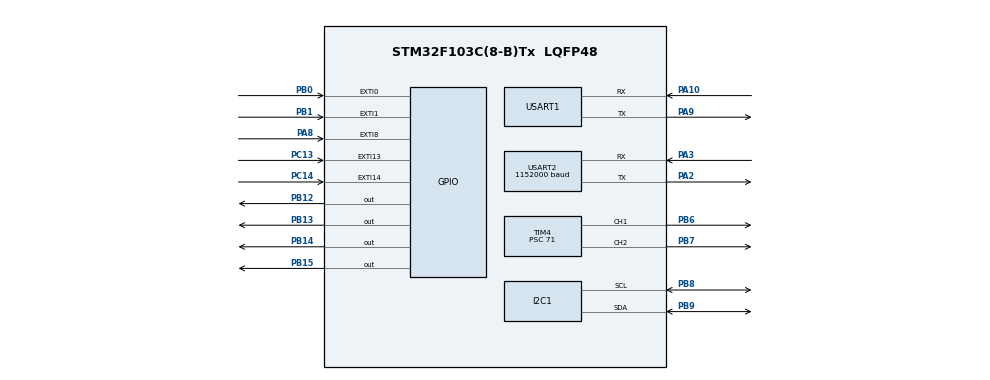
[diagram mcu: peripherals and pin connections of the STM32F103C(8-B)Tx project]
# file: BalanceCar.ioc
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Mcu.Family=STM32F1
Mcu.Name=STM32F103C(8-B)Tx
Mcu.Package=LQFP48
NVIC.EXTI0_IRQn=true\:0\:0\:true\:false\:true\:true\:true
NVIC.EXTI15_10_IRQn=true\:0\:0\:true\:false\:true\:true\:true
NVIC.EXTI1_IRQn=true\:0\:0\:true\:false\:true\:true\:true
NVIC.EXTI9_5_IRQn=true\:1\:0\:true\:false\:true\:true\:true
NVIC.PriorityGroup=NVIC_PRIORITYGROUP_4
NVIC.TIM2_IRQn=true\:2\:0\:true\:false\:true\:true\:true
NVIC.USART1_IRQn=true\:1\:0\:true\:false\:true\:true\:true
NVIC.USART2_IRQn=true\:0\:0\:true\:false\:true\:true\:true
PA10.Mode=Asynchronous
PA10.Signal=USART1_RX
PA13.Mode=Serial_Wire
PA13.Signal=SYS_JTMS-SWDIO
PA14.Mode=Serial_Wire
PA14.Signal=SYS_JTCK-SWCLK
PA2.Mode=Asynchronous
PA2.Signal=USART2_TX
PA3.Mode=Asynchronous
PA3.Signal=USART2_RX
PA8.GPIO_ModeDefaultEXTI=GPIO_MODE_IT_FALLING
PA8.GPIO_PuPd=GPIO_NOPULL
PA8.Signal=GPXTI8
PA9.Mode=Asynchronous
PA9.Signal=USART1_TX
PB0.GPIO_PuPd=GPIO_PULLDOWN
PB0.Signal=GPXTI0
PB1.GPIO_PuPd=GPIO_PULLDOWN
PB1.Signal=GPXTI1
PB12.Signal=GPIO_Output
PB13.Signal=GPIO_Output
PB14.Signal=GPIO_Output
PB15.Signal=GPIO_Output
PB6.Signal=S_TIM4_CH1
PB7.Signal=S_TIM4_CH2
PB8.Mode=I2C
PB8.Signal=I2C1_SCL
PB9.Mode=I2C
PB9.Signal=I2C1_SDA
PC13-TAMPER-RTC.Signal=GPXTI13
PC14-OSC32_IN.Signal=GPXTI14
PD0-OSC_IN.Mode=HSE-External-Oscillator
PD0-OSC_IN.Signal=RCC_OSC_IN
PD1-OSC_OUT.Mode=HSE-External-Oscillator
PD1-OSC_OUT.Signal=RCC_OSC_OUT
ProjectManager.HeapSize=0x200
ProjectManager.StackSize=0x400
ProjectManager.TargetToolchain=STM32CubeIDE
RCC.AHBFreq_Value=72000000
RCC.APB1CLKDivider=RCC_HCLK_DIV2
RCC.APB1Freq_Value=36000000
RCC.APB1TimFreq_Value=72000000
RCC.APB2Freq_Value=72000000
RCC.APB2TimFreq_Value=72000000
RCC.HCLKFreq_Value=72000000
RCC.PLLMUL=RCC_PLL_MUL9
RCC.PLLSourceVirtual=RCC_PLLSOURCE_HSE
RCC.SYSCLKFreq_VALUE=72000000
RCC.SYSCLKSource=RCC_SYSCLKSOURCE_PLLCLK
RCC.USBFreq_Value=72000000
SH.S_TIM4_CH1.0=TIM4_CH1,PWM Generation1 CH1
SH.S_TIM4_CH2.0=TIM4_CH2,PWM Generation2 CH2
TIM4.Channel-PWM\ Generation1\ CH1=TIM_CHANNEL_1
TIM4.Channel-PWM\ Generation2\ CH2=TIM_CHANNEL_2
TIM4.Period=999
TIM4.Prescaler=71
USART1.VirtualMode=VM_ASYNC
USART2.BaudRate=1152000
USART2.VirtualMode=VM_ASYNC
VP_TIM2_VS_ClockSourceINT.Mode=Internal
board=custom

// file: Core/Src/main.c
/* USER CODE BEGIN Header */
/**
  ******************************************************************************
  * @file           : main.c
  * @brief          : Main program body
  ******************************************************************************
  * @attention
  *
  * <h2><center>&copy; Copyright (c) 2021 STMicroelectronics.
  * All rights reserved.</center></h2>
  *
  * This software component is licensed by ST under BSD 3-Clause license,
  * the "License"; You may not use this file except in compliance with the
  * License. You may obtain a copy of the License at:
  *                        opensource.org/licenses/BSD-3-Clause
  *
  ******************************************************************************
  */
/* USER CODE END Header */
#include "main.h"

/* USER CODE BEGIN Includes */
#include "App.h"
/* USER CODE END Includes */

I2C_HandleTypeDef hi2c1;

void SystemClock_Config(void);
static void MX_GPIO_Init(void);
static void MX_TIM2_Init(void);
static void MX_TIM4_Init(void);
static void MX_USART1_UART_Init(void);
static void MX_USART2_UART_Init(void);
static void MX_I2C1_Init(void);

int main(void)
{

  /* MCU Configuration--------------------------------------------------------*/

  /* Reset of all peripherals, Initializes the Flash interface and the Systick. */
  HAL_Init();

  /* Configure the system clock */
  SystemClock_Config();

  /* Initialize all configured peripherals */
  MX_GPIO_Init();
  MX_TIM2_Init();
  MX_TIM4_Init();
  MX_USART1_UART_Init();
  MX_USART2_UART_Init();
  MX_I2C1_Init();
  /* USER CODE BEGIN 2 */

  App();
  /* USER CODE END 2 */

  /* Infinite loop */
  while (1)
  {

  }
}

void SystemClock_Config(void)
{
  LL_FLASH_SetLatency(LL_FLASH_LATENCY_2);
  while(LL_FLASH_GetLatency()!= LL_FLASH_LATENCY_2)
  {
  }
  LL_RCC_HSE_Enable();

   /* Wait till HSE is ready */
  while(LL_RCC_HSE_IsReady() != 1)
  {

  }
  LL_RCC_PLL_ConfigDomain_SYS(LL_RCC_PLLSOURCE_HSE_DIV_1, LL_RCC_PLL_MUL_9);
  LL_RCC_PLL_Enable();

   /* Wait till PLL is ready */
  while(LL_RCC_PLL_IsReady() != 1)
  {

  }
  LL_RCC_SetAHBPrescaler(LL_RCC_SYSCLK_DIV_1);
  LL_RCC_SetAPB1Prescaler(LL_RCC_APB1_DIV_2);
  LL_RCC_SetAPB2Prescaler(LL_RCC_APB2_DIV_1);
  LL_RCC_SetSysClkSource(LL_RCC_SYS_CLKSOURCE_PLL);

   /* Wait till System clock is ready */
  while(LL_RCC_GetSysClkSource() != LL_RCC_SYS_CLKSOURCE_STATUS_PLL)
  {

  }
  LL_SetSystemCoreClock(72000000);

   /* Update the time base */
  if (HAL_InitTick (TICK_INT_PRIORITY) != HAL_OK)
  {
    Error_Handler();
  }
}

static void MX_I2C1_Init(void)
{

  hi2c1.Instance = I2C1;
  hi2c1.Init.ClockSpeed = 100000;
  hi2c1.Init.DutyCycle = I2C_DUTYCYCLE_2;
  hi2c1.Init.OwnAddress1 = 0;
  hi2c1.Init.AddressingMode = I2C_ADDRESSINGMODE_7BIT;
  hi2c1.Init.DualAddressMode = I2C_DUALADDRESS_DISABLE;
  hi2c1.Init.OwnAddress2 = 0;
  hi2c1.Init.GeneralCallMode = I2C_GENERALCALL_DISABLE;
  hi2c1.Init.NoStretchMode = I2C_NOSTRETCH_DISABLE;
  if (HAL_I2C_Init(&hi2c1) != HAL_OK)
  {
    Error_Handler();
  }

}

static void MX_TIM2_Init(void)
{

  LL_TIM_InitTypeDef TIM_InitStruct = {0};

  /* Peripheral clock enable */
  LL_APB1_GRP1_EnableClock(LL_APB1_GRP1_PERIPH_TIM2);

  /* TIM2 interrupt Init */
  NVIC_SetPriority(TIM2_IRQn, NVIC_EncodePriority(NVIC_GetPriorityGrouping(),2, 0));
  NVIC_EnableIRQ(TIM2_IRQn);

  TIM_InitStruct.Prescaler = 0;
  TIM_InitStruct.CounterMode = LL_TIM_COUNTERMODE_UP;
  TIM_InitStruct.Autoreload = 65535;
  TIM_InitStruct.ClockDivision = LL_TIM_CLOCKDIVISION_DIV1;
  LL_TIM_Init(TIM2, &TIM_InitStruct);
  LL_TIM_DisableARRPreload(TIM2);
  LL_TIM_SetClockSource(TIM2, LL_TIM_CLOCKSOURCE_INTERNAL);
  LL_TIM_SetTriggerOutput(TIM2, LL_TIM_TRGO_RESET);
  LL_TIM_DisableMasterSlaveMode(TIM2);

}

static void MX_TIM4_Init(void)
{

  LL_TIM_InitTypeDef TIM_InitStruct = {0};
  LL_TIM_OC_InitTypeDef TIM_OC_InitStruct = {0};

  LL_GPIO_InitTypeDef GPIO_InitStruct = {0};

  /* Peripheral clock enable */
  LL_APB1_GRP1_EnableClock(LL_APB1_GRP1_PERIPH_TIM4);

  TIM_InitStruct.Prescaler = 71;
  TIM_InitStruct.CounterMode = LL_TIM_COUNTERMODE_UP;
  TIM_InitStruct.Autoreload = 999;
  TIM_InitStruct.ClockDivision = LL_TIM_CLOCKDIVISION_DIV1;
  LL_TIM_Init(TIM4, &TIM_InitStruct);
  LL_TIM_DisableARRPreload(TIM4);
  LL_TIM_OC_EnablePreload(TIM4, LL_TIM_CHANNEL_CH1);
  TIM_OC_InitStruct.OCMode = LL_TIM_OCMODE_PWM1;
  TIM_OC_InitStruct.OCState = LL_TIM_OCSTATE_DISABLE;
  TIM_OC_InitStruct.OCNState = LL_TIM_OCSTATE_DISABLE;
  TIM_OC_InitStruct.CompareValue = 0;
  TIM_OC_InitStruct.OCPolarity = LL_TIM_OCPOLARITY_HIGH;
  LL_TIM_OC_Init(TIM4, LL_TIM_CHANNEL_CH1, &TIM_OC_InitStruct);
  LL_TIM_OC_DisableFast(TIM4, LL_TIM_CHANNEL_CH1);
  LL_TIM_OC_EnablePreload(TIM4, LL_TIM_CHANNEL_CH2);
  LL_TIM_OC_Init(TIM4, LL_TIM_CHANNEL_CH2, &TIM_OC_InitStruct);
  LL_TIM_OC_DisableFast(TIM4, LL_TIM_CHANNEL_CH2);
  LL_TIM_SetTriggerOutput(TIM4, LL_TIM_TRGO_RESET);
  LL_TIM_DisableMasterSlaveMode(TIM4);
  LL_APB2_GRP1_EnableClock(LL_APB2_GRP1_PERIPH_GPIOB);
  /**TIM4 GPIO Configuration
  PB6   ------> TIM4_CH1
  PB7   ------> TIM4_CH2
  */
  GPIO_InitStruct.Pin = LL_GPIO_PIN_6|LL_GPIO_PIN_7;
  GPIO_InitStruct.Mode = LL_GPIO_MODE_ALTERNATE;
  GPIO_InitStruct.Speed = LL_GPIO_SPEED_FREQ_LOW;
  GPIO_InitStruct.OutputType = LL_GPIO_OUTPUT_PUSHPULL;
  LL_GPIO_Init(GPIOB, &GPIO_InitStruct);

}

static void MX_USART1_UART_Init(void)
{

  LL_USART_InitTypeDef USART_InitStruct = {0};

  LL_GPIO_InitTypeDef GPIO_InitStruct = {0};

  /* Peripheral clock enable */
  LL_APB2_GRP1_EnableClock(LL_APB2_GRP1_PERIPH_USART1);

  LL_APB2_GRP1_EnableClock(LL_APB2_GRP1_PERIPH_GPIOA);
  /**USART1 GPIO Configuration
  PA9   ------> USART1_TX
  PA10   ------> USART1_RX
  */
  GPIO_InitStruct.Pin = LL_GPIO_PIN_9;
  GPIO_InitStruct.Mode = LL_GPIO_MODE_ALTERNATE;
  GPIO_InitStruct.Speed = LL_GPIO_SPEED_FREQ_HIGH;
  GPIO_InitStruct.OutputType = LL_GPIO_OUTPUT_PUSHPULL;
  LL_GPIO_Init(GPIOA, &GPIO_InitStruct);

  GPIO_InitStruct.Pin = LL_GPIO_PIN_10;
  GPIO_InitStruct.Mode = LL_GPIO_MODE_FLOATING;
  LL_GPIO_Init(GPIOA, &GPIO_InitStruct);

  /* USART1 interrupt Init */
  NVIC_SetPriority(USART1_IRQn, NVIC_EncodePriority(NVIC_GetPriorityGrouping(),1, 0));
  NVIC_EnableIRQ(USART1_IRQn);

  USART_InitStruct.BaudRate = 115200;
  USART_InitStruct.DataWidth = LL_USART_DATAWIDTH_8B;
  USART_InitStruct.StopBits = LL_USART_STOPBITS_1;
  USART_InitStruct.Parity = LL_USART_PARITY_NONE;
  USART_InitStruct.TransferDirection = LL_USART_DIRECTION_TX_RX;
  USART_InitStruct.HardwareFlowControl = LL_USART_HWCONTROL_NONE;
  USART_InitStruct.OverSampling = LL_USART_OVERSAMPLING_16;
  LL_USART_Init(USART1, &USART_InitStruct);
  LL_USART_ConfigAsyncMode(USART1);
  LL_USART_Enable(USART1);

}

static void MX_USART2_UART_Init(void)
{

  LL_USART_InitTypeDef USART_InitStruct = {0};

  LL_GPIO_InitTypeDef GPIO_InitStruct = {0};

  /* Peripheral clock enable */
  LL_APB1_GRP1_EnableClock(LL_APB1_GRP1_PERIPH_USART2);

  LL_APB2_GRP1_EnableClock(LL_APB2_GRP1_PERIPH_GPIOA);
  /**USART2 GPIO Configuration
  PA2   ------> USART2_TX
  PA3   ------> USART2_RX
  */
  GPIO_InitStruct.Pin = LL_GPIO_PIN_2;
  GPIO_InitStruct.Mode = LL_GPIO_MODE_ALTERNATE;
  GPIO_InitStruct.Speed = LL_GPIO_SPEED_FREQ_HIGH;
  GPIO_InitStruct.OutputType = LL_GPIO_OUTPUT_PUSHPULL;
  LL_GPIO_Init(GPIOA, &GPIO_InitStruct);

  GPIO_InitStruct.Pin = LL_GPIO_PIN_3;
  GPIO_InitStruct.Mode = LL_GPIO_MODE_FLOATING;
  LL_GPIO_Init(GPIOA, &GPIO_InitStruct);

  /* USART2 interrupt Init */
  NVIC_SetPriority(USART2_IRQn, NVIC_EncodePriority(NVIC_GetPriorityGrouping(),0, 0));
  NVIC_EnableIRQ(USART2_IRQn);

  USART_InitStruct.BaudRate = 1152000;
  USART_InitStruct.DataWidth = LL_USART_DATAWIDTH_8B;
  USART_InitStruct.StopBits = LL_USART_STOPBITS_1;
  USART_InitStruct.Parity = LL_USART_PARITY_NONE;
  USART_InitStruct.TransferDirection = LL_USART_DIRECTION_TX_RX;
  USART_InitStruct.HardwareFlowControl = LL_USART_HWCONTROL_NONE;
  USART_InitStruct.OverSampling = LL_USART_OVERSAMPLING_16;
  LL_USART_Init(USART2, &USART_InitStruct);
  LL_USART_ConfigAsyncMode(USART2);
  LL_USART_Enable(USART2);
  /* USER CODE BEGIN USART2_Init 2 */
  LL_USART_ClearFlag_RXNE(USART2);
  LL_USART_EnableIT_RXNE(USART2);
  /* USER CODE END USART2_Init 2 */

}

static void MX_GPIO_Init(void)
{
  LL_EXTI_InitTypeDef EXTI_InitStruct = {0};
  LL_GPIO_InitTypeDef GPIO_InitStruct = {0};

  /* GPIO Ports Clock Enable */
  LL_APB2_GRP1_EnableClock(LL_APB2_GRP1_PERIPH_GPIOC);
  LL_APB2_GRP1_EnableClock(LL_APB2_GRP1_PERIPH_GPIOD);
  LL_APB2_GRP1_EnableClock(LL_APB2_GRP1_PERIPH_GPIOA);
  LL_APB2_GRP1_EnableClock(LL_APB2_GRP1_PERIPH_GPIOB);

  /**/
  LL_GPIO_ResetOutputPin(GPIOB, LL_GPIO_PIN_12|LL_GPIO_PIN_13|LL_GPIO_PIN_14|LL_GPIO_PIN_15);

  /**/
  LL_GPIO_AF_SetEXTISource(LL_GPIO_AF_EXTI_PORTC, LL_GPIO_AF_EXTI_LINE13);

  /**/
  LL_GPIO_AF_SetEXTISource(LL_GPIO_AF_EXTI_PORTC, LL_GPIO_AF_EXTI_LINE14);

  /**/
  LL_GPIO_AF_SetEXTISource(LL_GPIO_AF_EXTI_PORTB, LL_GPIO_AF_EXTI_LINE0);

  /**/
  LL_GPIO_AF_SetEXTISource(LL_GPIO_AF_EXTI_PORTB, LL_GPIO_AF_EXTI_LINE1);

  /**/
  LL_GPIO_AF_SetEXTISource(LL_GPIO_AF_EXTI_PORTA, LL_GPIO_AF_EXTI_LINE8);

  /**/
  EXTI_InitStruct.Line_0_31 = LL_EXTI_LINE_13;
  EXTI_InitStruct.LineCommand = ENABLE;
  EXTI_InitStruct.Mode = LL_EXTI_MODE_IT;
  EXTI_InitStruct.Trigger = LL_EXTI_TRIGGER_RISING;
  LL_EXTI_Init(&EXTI_InitStruct);

  /**/
  EXTI_InitStruct.Line_0_31 = LL_EXTI_LINE_14;
  EXTI_InitStruct.LineCommand = ENABLE;
  EXTI_InitStruct.Mode = LL_EXTI_MODE_IT;
  EXTI_InitStruct.Trigger = LL_EXTI_TRIGGER_RISING;
  LL_EXTI_Init(&EXTI_InitStruct);

  /**/
  EXTI_InitStruct.Line_0_31 = LL_EXTI_LINE_0;
  EXTI_InitStruct.LineCommand = ENABLE;
  EXTI_InitStruct.Mode = LL_EXTI_MODE_IT;
  EXTI_InitStruct.Trigger = LL_EXTI_TRIGGER_RISING;
  LL_EXTI_Init(&EXTI_InitStruct);

  /**/
  EXTI_InitStruct.Line_0_31 = LL_EXTI_LINE_1;
  EXTI_InitStruct.LineCommand = ENABLE;
  EXTI_InitStruct.Mode = LL_EXTI_MODE_IT;
  EXTI_InitStruct.Trigger = LL_EXTI_TRIGGER_RISING;
  LL_EXTI_Init(&EXTI_InitStruct);

  /**/
  EXTI_InitStruct.Line_0_31 = LL_EXTI_LINE_8;
  EXTI_InitStruct.LineCommand = ENABLE;
  EXTI_InitStruct.Mode = LL_EXTI_MODE_IT;
  EXTI_InitStruct.Trigger = LL_EXTI_TRIGGER_FALLING;
  LL_EXTI_Init(&EXTI_InitStruct);

  /**/
  LL_GPIO_SetPinMode(GPIOC, LL_GPIO_PIN_13, LL_GPIO_MODE_FLOATING);

  /**/
  LL_GPIO_SetPinMode(GPIOC, LL_GPIO_PIN_14, LL_GPIO_MODE_FLOATING);

  /**/
  LL_GPIO_SetPinMode(GPIOB, LL_GPIO_PIN_0, LL_GPIO_MODE_INPUT);

  /**/
  LL_GPIO_SetPinMode(GPIOB, LL_GPIO_PIN_1, LL_GPIO_MODE_INPUT);

  /**/
  LL_GPIO_SetPinMode(GPIOA, LL_GPIO_PIN_8, LL_GPIO_MODE_FLOATING);

  /**/
  LL_GPIO_SetPinPull(GPIOB, LL_GPIO_PIN_0, LL_GPIO_PULL_DOWN);

  /**/
  LL_GPIO_SetPinPull(GPIOB, LL_GPIO_PIN_1, LL_GPIO_PULL_DOWN);

  /**/
  GPIO_InitStruct.Pin = LL_GPIO_PIN_12|LL_GPIO_PIN_13|LL_GPIO_PIN_14|LL_GPIO_PIN_15;
  GPIO_InitStruct.Mode = LL_GPIO_MODE_OUTPUT;
  GPIO_InitStruct.Speed = LL_GPIO_SPEED_FREQ_LOW;
  GPIO_InitStruct.OutputType = LL_GPIO_OUTPUT_PUSHPULL;
  LL_GPIO_Init(GPIOB, &GPIO_InitStruct);

  /* EXTI interrupt init*/
  NVIC_SetPriority(EXTI0_IRQn, NVIC_EncodePriority(NVIC_GetPriorityGrouping(),0, 0));
  NVIC_EnableIRQ(EXTI0_IRQn);
  NVIC_SetPriority(EXTI1_IRQn, NVIC_EncodePriority(NVIC_GetPriorityGrouping(),0, 0));
  NVIC_EnableIRQ(EXTI1_IRQn);
  NVIC_SetPriority(EXTI9_5_IRQn, NVIC_EncodePriority(NVIC_GetPriorityGrouping(),1, 0));
  NVIC_EnableIRQ(EXTI9_5_IRQn);
  NVIC_SetPriority(EXTI15_10_IRQn, NVIC_EncodePriority(NVIC_GetPriorityGrouping(),0, 0));
  NVIC_EnableIRQ(EXTI15_10_IRQn);

}

void Error_Handler(void)
{
  __disable_irq();
  while (1)
  {
  }
}

/************************ (C) COPYRIGHT STMicroelectronics *****END OF FILE****/
